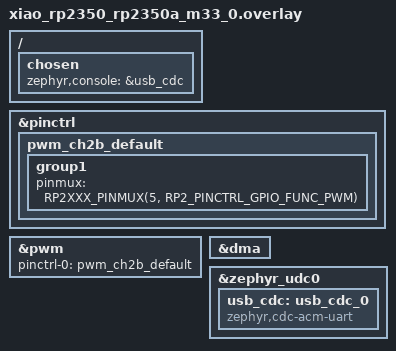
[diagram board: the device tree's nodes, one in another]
/*
 * XIAO RP2350 (untested on hardware - builds only). Same setup as
 * xiao_rp2040.overlay, but the expansion board's buzzer pin A3/D3 is
 * GPIO5 on this board, not GPIO29: PWM slice 2, channel B (slice =
 * (gpio >> 1) & 7, channel = gpio & 1) - see PWM_SLICE in main.c.
 * Also used by the Hazard3 (RISC-V) variant, see
 * xiao_rp2350_rp2350a_hazard3_0.overlay.
 */
#include <zephyr/dt-bindings/pinctrl/rpi-pico-rp2350a-pinctrl.h>
#include <zephyr/dt-bindings/gpio/gpio.h>

/ {
	chosen {
		zephyr,console = &usb_cdc;
	};
};

&pinctrl {
	pwm_ch2b_default: pwm_ch2b_default {
		group1 {
			pinmux = <RP2XXX_PINMUX(5, RP2_PINCTRL_GPIO_FUNC_PWM)>;
		};
	};
};

&pwm {
	status = "okay";
	pinctrl-0 = <&pwm_ch2b_default>;
	pinctrl-names = "default";
};

&dma {
	status = "okay";
};

&zephyr_udc0 {
	usb_cdc: usb_cdc_0 {
		compatible = "zephyr,cdc-acm-uart";
	};
};
